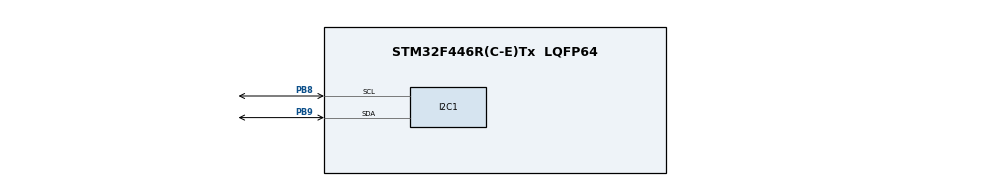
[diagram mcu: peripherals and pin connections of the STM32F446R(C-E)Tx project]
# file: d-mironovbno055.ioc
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Mcu.Family=STM32F4
Mcu.Name=STM32F446R(C-E)Tx
Mcu.Package=LQFP64
NVIC.PriorityGroup=NVIC_PRIORITYGROUP_4
PA13.Mode=Trace_Asynchronous_SW
PA13.Signal=SYS_JTMS-SWDIO
PA14.Mode=Trace_Asynchronous_SW
PA14.Signal=SYS_JTCK-SWCLK
PB3.Mode=Trace_Asynchronous_SW
PB3.Signal=SYS_JTDO-SWO
PB8.Mode=I2C
PB8.Signal=I2C1_SCL
PB9.Mode=I2C
PB9.Signal=I2C1_SDA
PC14-OSC32_IN.Mode=LSE-External-Oscillator
PC14-OSC32_IN.Signal=RCC_OSC32_IN
PC15-OSC32_OUT.Mode=LSE-External-Oscillator
PC15-OSC32_OUT.Signal=RCC_OSC32_OUT
PH0-OSC_IN.Mode=HSE-External-Oscillator
PH0-OSC_IN.Signal=RCC_OSC_IN
PH1-OSC_OUT.Mode=HSE-External-Oscillator
PH1-OSC_OUT.Signal=RCC_OSC_OUT
ProjectManager.HeapSize=0x200
ProjectManager.StackSize=0x400
ProjectManager.TargetToolchain=STM32CubeIDE
RCC.CortexFreq_Value=16000000
RCC.USBFreq_Value=96000000
RCC.VCOOutputFreq_Value=192000000
board=custom

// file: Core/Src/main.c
/* USER CODE BEGIN Header */
/**
  ******************************************************************************
  * @file           : main.c
  * @brief          : Main program body
  ******************************************************************************
  * @attention
  *
  * Copyright (c) 2025 STMicroelectronics.
  * All rights reserved.
  *
  * This software is licensed under terms that can be found in the LICENSE file
  * in the root directory of this software component.
  * If no LICENSE file comes with this software, it is provided AS-IS.
  *
  ******************************************************************************
  */
/* USER CODE END Header */
#include "main.h"

/* USER CODE BEGIN Includes */
#include <stdbool.h>
#include <stdio.h>
#include "bno055.h"
#include "bno_config.h"
#include "stm32f4xx_hal.h"
#include "stm32f4xx_hal_gpio.h"
#include "stm32f4xx_hal_gpio_ex.h"
/* USER CODE END Includes */

/* USER CODE BEGIN PD */
float accx,accy,accz;

int _write(int file, char *ptr, int len)
{
  /* Implement your write code here, this is used by puts and printf for example */
  int i=0;
  for(i=0 ; i<len ; i++)
    ITM_SendChar((*ptr++));
  return len;
}
/* USER CODE END PD */

I2C_HandleTypeDef hi2c1;

/* USER CODE BEGIN PV */
bno055_t bno;
error_bno err;
/* USER CODE END PV */

void SystemClock_Config(void);
static void MX_GPIO_Init(void);
static void MX_I2C1_Init(void);

int main(void)
{

  /* MCU Configuration--------------------------------------------------------*/

  /* Reset of all peripherals, Initializes the Flash interface and the Systick. */
  HAL_Init();

  /* Configure the system clock */
  SystemClock_Config();

  /* Initialize all configured peripherals */
  MX_GPIO_Init();
  MX_I2C1_Init();
  /* USER CODE BEGIN 2 */
  bno = (bno055_t){
      .i2c = &hi2c1, .addr = BNO_ADDR, .mode = BNO_MODE_IMU, ._temp_unit = 0,
  };
  HAL_Delay(1000);
  if ((err = bno055_init(&bno)) == BNO_OK) {
	  printf("[+] BNO055 init success\r\n");
      HAL_Delay(100);
  } else {
      printf("[!] BNO055 init failed\r\n");
      printf("%s\n", bno055_err_str(err));
      Error_Handler();
      }
      HAL_Delay(100);
      err = bno055_set_unit(&bno, BNO_TEMP_UNIT_C, BNO_GYR_UNIT_DPS,
                            BNO_ACC_UNITSEL_M_S2, BNO_EUL_UNIT_DEG);
   if (err != BNO_OK) {
	   printf("[BNO] Failed to set units. Err: %d\r\n", err);
   } else {
	   printf("[BNO] Unit selection success\r\n");
     }
   HAL_Delay(1000);
   s8 temperature = 0;
   // f32 acc_x = 0.0f, acc_y = 0.0f, acc_z = 0.0f;

   bno055_vec3_t acc = {0, 0, 0};
   bno055_vec3_t lia = {0, 0, 0};
   bno055_vec3_t gyr = {0, 0, 0};
   bno055_vec3_t mag = {0, 0, 0};
   bno055_vec3_t grv = {0, 0, 0};
   bno055_euler_t eul = {0, 0, 0};
   bno055_vec4_t qua = {0, 0, 0};
  /* USER CODE END 2 */

  /* Infinite loop */
  while (1)
  {

    /* USER CODE BEGIN 3 */
	  bno.temperature(&bno, &temperature);
	  bno.acc(&bno, &acc);
	  bno.linear_acc(&bno, &lia);
	  bno.gyro(&bno, &gyr);
	  bno.mag(&bno, &mag);
	  bno.gravity(&bno, &grv);
	  bno.euler(&bno, &eul);
	  bno.quaternion(&bno, &qua);
	  accx = acc.x;
	  accy = acc.y;
	  accz = acc.z;
	  printf("test\n");
	  //printf("[+] Temperature: %2d°C\r\n", temperature);
	  printf("[+] ACC - x: %+2.2f | y: %+2.2f | z: %+2.2f\r\n", acc.x, acc.y, acc.z);
	  printf("[+] LIA - x: %+2.2f | y: %+2.2f | z: %+2.2f\r\n", lia.x, lia.y, lia.z);
	  printf("[+] GYR - x: %+2.2f | y: %+2.2f | z: %+2.2f\r\n", gyr.x, gyr.y, gyr.z);
	  printf("[+] MAG - x: %+2.2f | y: %+2.2f | z: %+2.2f\r\n", mag.x, mag.y, mag.z);
	  printf("[+] GRV - x: %+2.2f | y: %+2.2f | z: %+2.2f\r\n", grv.x, grv.y, grv.z);
	  printf("[+] Roll: %+2.2f | Pitch: %+2.2f | Yaw: %+2.2f\r\n", eul.roll, eul.pitch, eul.yaw);
	  printf("[+] QUA - w: %+2.2f | x: %+2.2f | y: %+2.2f | z: %+2.2f\r\n", qua.w, qua.x, qua.y, qua.z);
	  HAL_Delay(100);

  }
  /* USER CODE END 3 */
}

void SystemClock_Config(void)
{
  RCC_OscInitTypeDef RCC_OscInitStruct = {0};
  RCC_ClkInitTypeDef RCC_ClkInitStruct = {0};

  /** Configure the main internal regulator output voltage
  */
  __HAL_RCC_PWR_CLK_ENABLE();
  __HAL_PWR_VOLTAGESCALING_CONFIG(PWR_REGULATOR_VOLTAGE_SCALE3);

  /** Initializes the RCC Oscillators according to the specified parameters
  * in the RCC_OscInitTypeDef structure.
  */
  RCC_OscInitStruct.OscillatorType = RCC_OSCILLATORTYPE_HSI;
  RCC_OscInitStruct.HSIState = RCC_HSI_ON;
  RCC_OscInitStruct.HSICalibrationValue = RCC_HSICALIBRATION_DEFAULT;
  RCC_OscInitStruct.PLL.PLLState = RCC_PLL_NONE;
  if (HAL_RCC_OscConfig(&RCC_OscInitStruct) != HAL_OK)
  {
    Error_Handler();
  }

  /** Initializes the CPU, AHB and APB buses clocks
  */
  RCC_ClkInitStruct.ClockType = RCC_CLOCKTYPE_HCLK|RCC_CLOCKTYPE_SYSCLK
                              |RCC_CLOCKTYPE_PCLK1|RCC_CLOCKTYPE_PCLK2;
  RCC_ClkInitStruct.SYSCLKSource = RCC_SYSCLKSOURCE_HSI;
  RCC_ClkInitStruct.AHBCLKDivider = RCC_SYSCLK_DIV1;
  RCC_ClkInitStruct.APB1CLKDivider = RCC_HCLK_DIV1;
  RCC_ClkInitStruct.APB2CLKDivider = RCC_HCLK_DIV1;

  if (HAL_RCC_ClockConfig(&RCC_ClkInitStruct, FLASH_LATENCY_0) != HAL_OK)
  {
    Error_Handler();
  }
}

static void MX_I2C1_Init(void)
{

  /* USER CODE BEGIN I2C1_Init 0 */
  __HAL_RCC_I2C1_CLK_ENABLE();
  /* USER CODE END I2C1_Init 0 */

  hi2c1.Instance = I2C1;
  hi2c1.Init.ClockSpeed = 100000;
  hi2c1.Init.DutyCycle = I2C_DUTYCYCLE_2;
  hi2c1.Init.OwnAddress1 = 0;
  hi2c1.Init.AddressingMode = I2C_ADDRESSINGMODE_7BIT;
  hi2c1.Init.DualAddressMode = I2C_DUALADDRESS_DISABLE;
  hi2c1.Init.OwnAddress2 = 0;
  hi2c1.Init.GeneralCallMode = I2C_GENERALCALL_DISABLE;
  hi2c1.Init.NoStretchMode = I2C_NOSTRETCH_DISABLE;
  if (HAL_I2C_Init(&hi2c1) != HAL_OK)
  {
    Error_Handler();
  }

}

static void MX_GPIO_Init(void)
{

  /* GPIO Ports Clock Enable */
  __HAL_RCC_GPIOC_CLK_ENABLE();
  __HAL_RCC_GPIOH_CLK_ENABLE();
  __HAL_RCC_GPIOA_CLK_ENABLE();
  __HAL_RCC_GPIOB_CLK_ENABLE();

}

void Error_Handler(void)
{
  /* USER CODE BEGIN Error_Handler_Debug */
  /* User can add his own implementation to report the HAL error return state */
  __disable_irq();
  while (1)
  {
	  printf("Init Failed \n");
	  HAL_Delay(100);

  }
  /* USER CODE END Error_Handler_Debug */
}
